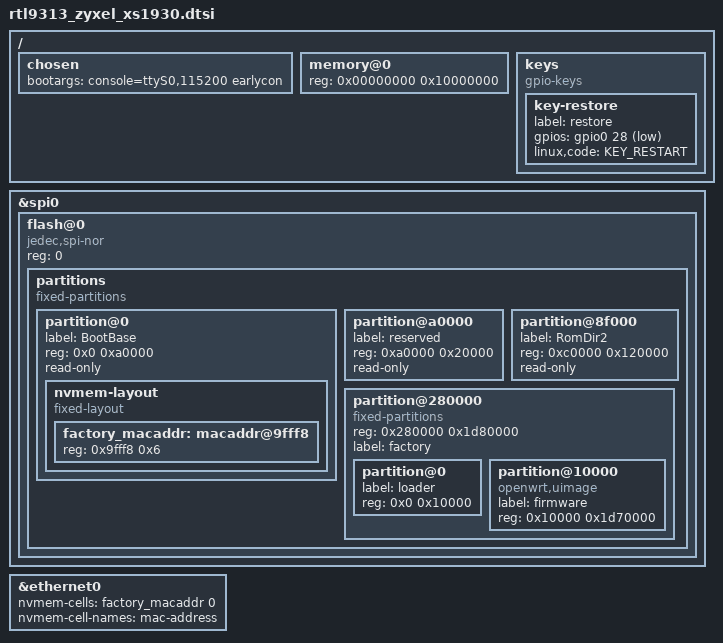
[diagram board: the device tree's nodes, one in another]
// SPDX-License-Identifier: GPL-2.0-or-later
/dts-v1/;

#include "rtl931x.dtsi"

#include <dt-bindings/input/input.h>
#include <dt-bindings/gpio/gpio.h>
#include <dt-bindings/leds/common.h>
#include <dt-bindings/mux/mux.h>

/ {
	chosen {
		bootargs = "console=ttyS0,115200 earlycon";
	};

	memory@0 {
		device_type = "memory";
		reg = <0x00000000 0x10000000>;
	};

	keys {
		compatible = "gpio-keys";

		key-restore {
			label = "restore";
			gpios = <&gpio0 28 GPIO_ACTIVE_LOW>;
			linux,code = <KEY_RESTART>;
		};
	};
};

&spi0 {
	status = "okay";

	flash@0 {
		compatible = "jedec,spi-nor";
		reg = <0>;

		partitions {
			compatible = "fixed-partitions";
			#address-cells = <1>;
			#size-cells = <1>;

			partition@0 {
				label = "BootBase";
				reg = <0x0 0xa0000>;
				read-only;

				nvmem-layout {
					compatible = "fixed-layout";
					#address-cells = <1>;
					#size-cells = <1>;

					factory_macaddr: macaddr@9fff8 {
						reg = <0x9fff8 0x6>;
					};
				};
			};

			/* DbgArea */
			partition@a0000 {
				label = "reserved";
				reg = <0xa0000 0x20000>;
				read-only;
			};

			partition@8f000 {
				label = "RomDir2";
				reg = <0xc0000 0x120000>;
				read-only;

				/* boot image index at offset 0x151 */
			};

			partition@280000 {
				reg = <0x280000 0x1d80000>;
			//	reg = <0x280000 0x1000000>; dual-image support	
				label = "factory";

				compatible = "fixed-partitions";
				#address-cells = <1>;
				#size-cells = <1>;

				partition@0 {
					label = "loader";
					reg = <0x0 0x10000>;
				};

				partition@10000 {
					label = "firmware";
					reg = <0x10000 0x1d70000>;
					compatible = "openwrt,uimage", "denx,uimage";
				};
			};

			/*
			partition@1280000 {
				reg = <0x1280000 0xd80000>;
				label = "factory2";

				compatible = "fixed-partitions";
				#address-cells = <1>;
				#size-cells = <1>;

				partition@0 {
					label = "loader2";
					reg = <0x0 0x10000>;
				};

				partition@10000 {
					label = "firmware2";
					reg = <0x10000 0xd70000>;
					compatible = "openwrt,uimage", "denx,uimage";
				};
			};
			*/
		};
	};
};

&ethernet0 {
	nvmem-cells = <&factory_macaddr 0>;
	nvmem-cell-names = "mac-address";
};
